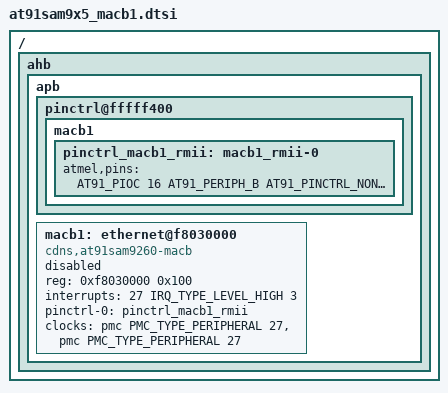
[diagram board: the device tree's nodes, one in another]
#include <dt-bindings/pinctrl/at91.h>
#include <dt-bindings/interrupt-controller/irq.h>
/ {
	ahb {
		apb {
			pinctrl@fffff400 {
				macb1 {
					pinctrl_macb1_rmii: macb1_rmii-0 {
						atmel,pins =
							<AT91_PIOC 16 AT91_PERIPH_B AT91_PINCTRL_NONE	 
							 AT91_PIOC 18 AT91_PERIPH_B AT91_PINCTRL_NONE	 
							 AT91_PIOC 19 AT91_PERIPH_B AT91_PINCTRL_NONE	 
							 AT91_PIOC 20 AT91_PERIPH_B AT91_PINCTRL_NONE	 
							 AT91_PIOC 21 AT91_PERIPH_B AT91_PINCTRL_NONE	 
							 AT91_PIOC 27 AT91_PERIPH_B AT91_PINCTRL_NONE	 
							 AT91_PIOC 28 AT91_PERIPH_B AT91_PINCTRL_NONE	 
							 AT91_PIOC 29 AT91_PERIPH_B AT91_PINCTRL_NONE	 
							 AT91_PIOC 30 AT91_PERIPH_B AT91_PINCTRL_NONE	 
							 AT91_PIOC 31 AT91_PERIPH_B AT91_PINCTRL_NONE>;	 
					};
				};
			};
			macb1: ethernet@f8030000 {
				compatible = "cdns,at91sam9260-macb", "cdns,macb";
				reg = <0xf8030000 0x100>;
				interrupts = <27 IRQ_TYPE_LEVEL_HIGH 3>;
				pinctrl-names = "default";
				pinctrl-0 = <&pinctrl_macb1_rmii>;
				clocks = <&pmc PMC_TYPE_PERIPHERAL 27>, <&pmc PMC_TYPE_PERIPHERAL 27>;
				clock-names = "hclk", "pclk";
				status = "disabled";
			};
		};
	};
};
